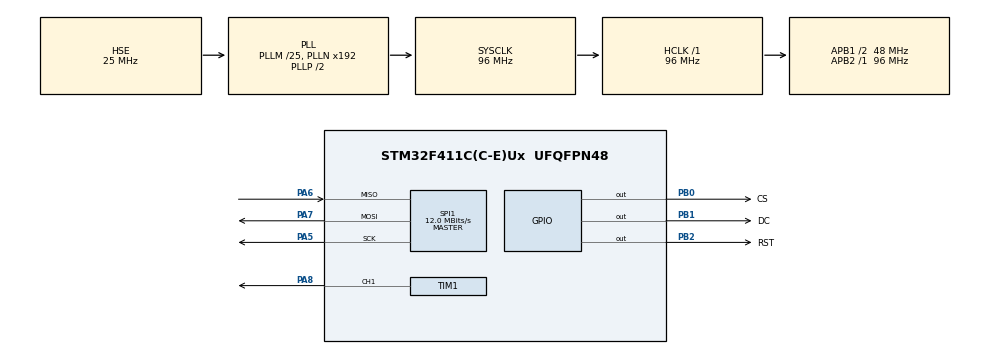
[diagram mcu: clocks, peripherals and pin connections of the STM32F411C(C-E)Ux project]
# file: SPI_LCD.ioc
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Mcu.Family=STM32F4
Mcu.Name=STM32F411C(C-E)Ux
Mcu.Package=UFQFPN48
NVIC.PriorityGroup=NVIC_PRIORITYGROUP_4
PA5.Mode=Full_Duplex_Master
PA5.Signal=SPI1_SCK
PA6.Mode=Full_Duplex_Master
PA6.Signal=SPI1_MISO
PA7.Mode=Full_Duplex_Master
PA7.Signal=SPI1_MOSI
PA8.Signal=S_TIM1_CH1
PB0.GPIO_Label=CS
PB0.PinState=GPIO_PIN_SET
PB0.Signal=GPIO_Output
PB1.GPIO_Label=DC
PB1.PinState=GPIO_PIN_SET
PB1.Signal=GPIO_Output
PB2.GPIO_Label=RST
PB2.PinState=GPIO_PIN_SET
PB2.Signal=GPIO_Output
PC14-OSC32_IN.Mode=LSE-External-Oscillator
PC14-OSC32_IN.Signal=RCC_OSC32_IN
PC15-OSC32_OUT.Mode=LSE-External-Oscillator
PC15-OSC32_OUT.Signal=RCC_OSC32_OUT
PH0\ -\ OSC_IN.Mode=HSE-External-Oscillator
PH0\ -\ OSC_IN.Signal=RCC_OSC_IN
PH1\ -\ OSC_OUT.Mode=HSE-External-Oscillator
PH1\ -\ OSC_OUT.Signal=RCC_OSC_OUT
ProjectManager.HeapSize=0x200
ProjectManager.StackSize=0x400
ProjectManager.TargetToolchain=Makefile
RCC.48MHZClocksFreq_Value=48000000
RCC.AHBFreq_Value=96000000
RCC.APB1CLKDivider=RCC_HCLK_DIV2
RCC.APB1Freq_Value=48000000
RCC.APB1TimFreq_Value=96000000
RCC.APB2Freq_Value=96000000
RCC.APB2TimFreq_Value=96000000
RCC.CortexFreq_Value=96000000
RCC.HCLKFreq_Value=96000000
RCC.HSE_VALUE=25000000
RCC.HSI_VALUE=16000000
RCC.PLLM=25
RCC.PLLSourceVirtual=RCC_PLLSOURCE_HSE
RCC.SYSCLKFreq_VALUE=96000000
RCC.SYSCLKSource=RCC_SYSCLKSOURCE_PLLCLK
RCC.VCOOutputFreq_Value=192000000
SH.S_TIM1_CH1.0=TIM1_CH1,PWM Generation1 CH1
SPI1.BaudRatePrescaler=SPI_BAUDRATEPRESCALER_8
SPI1.CalculateBaudRate=12.0 MBits/s
SPI1.Direction=SPI_DIRECTION_2LINES
SPI1.Mode=SPI_MODE_MASTER
SPI1.VirtualType=VM_MASTER
TIM1.AutoReloadPreload=TIM_AUTORELOAD_PRELOAD_ENABLE
TIM1.Channel-PWM\ Generation1\ CH1=TIM_CHANNEL_1
TIM1.Period=1000-1
board=custom

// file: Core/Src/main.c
/* USER CODE BEGIN Header */
/**
  ******************************************************************************
  * @file           : main.c
  * @brief          : Main program body
  ******************************************************************************
  * @attention
  *
  * Copyright (c) 2025 STMicroelectronics.
  * All rights reserved.
  *
  * This software is licensed under terms that can be found in the LICENSE file
  * in the root directory of this software component.
  * If no LICENSE file comes with this software, it is provided AS-IS.
  *
  ******************************************************************************
  */
/* USER CODE END Header */
#include "main.h"

/* USER CODE BEGIN Includes */
#include "lcd.h"

/* USER CODE END Includes */

SPI_HandleTypeDef hspi1;

TIM_HandleTypeDef htim1;

void SystemClock_Config(void);
static void MX_GPIO_Init(void);
static void MX_SPI1_Init(void);
static void MX_TIM1_Init(void);

int main(void)
{

  /* MCU Configuration--------------------------------------------------------*/

  /* Reset of all peripherals, Initializes the Flash interface and the Systick. */
  HAL_Init();

  /* Configure the system clock */
  SystemClock_Config();

  /* Initialize all configured peripherals */
  MX_GPIO_Init();
  MX_SPI1_Init();
  MX_TIM1_Init();
  /* USER CODE BEGIN 2 */

  LCD_1in28_test();

  /* USER CODE END 2 */

  /* Infinite loop */
  while (1)
  {

  }
}

void SystemClock_Config(void)
{
  RCC_OscInitTypeDef RCC_OscInitStruct = {0};
  RCC_ClkInitTypeDef RCC_ClkInitStruct = {0};

  /** Configure the main internal regulator output voltage
  */
  __HAL_RCC_PWR_CLK_ENABLE();
  __HAL_PWR_VOLTAGESCALING_CONFIG(PWR_REGULATOR_VOLTAGE_SCALE1);

  /** Initializes the RCC Oscillators according to the specified parameters
  * in the RCC_OscInitTypeDef structure.
  */
  RCC_OscInitStruct.OscillatorType = RCC_OSCILLATORTYPE_HSE;
  RCC_OscInitStruct.HSEState = RCC_HSE_ON;
  RCC_OscInitStruct.PLL.PLLState = RCC_PLL_ON;
  RCC_OscInitStruct.PLL.PLLSource = RCC_PLLSOURCE_HSE;
  RCC_OscInitStruct.PLL.PLLM = 25;
  RCC_OscInitStruct.PLL.PLLN = 192;
  RCC_OscInitStruct.PLL.PLLP = RCC_PLLP_DIV2;
  RCC_OscInitStruct.PLL.PLLQ = 4;
  if (HAL_RCC_OscConfig(&RCC_OscInitStruct) != HAL_OK)
  {
    Error_Handler();
  }

  /** Initializes the CPU, AHB and APB buses clocks
  */
  RCC_ClkInitStruct.ClockType = RCC_CLOCKTYPE_HCLK|RCC_CLOCKTYPE_SYSCLK
                              |RCC_CLOCKTYPE_PCLK1|RCC_CLOCKTYPE_PCLK2;
  RCC_ClkInitStruct.SYSCLKSource = RCC_SYSCLKSOURCE_PLLCLK;
  RCC_ClkInitStruct.AHBCLKDivider = RCC_SYSCLK_DIV1;
  RCC_ClkInitStruct.APB1CLKDivider = RCC_HCLK_DIV2;
  RCC_ClkInitStruct.APB2CLKDivider = RCC_HCLK_DIV1;

  if (HAL_RCC_ClockConfig(&RCC_ClkInitStruct, FLASH_LATENCY_3) != HAL_OK)
  {
    Error_Handler();
  }
}

static void MX_SPI1_Init(void)
{

  /* SPI1 parameter configuration*/
  hspi1.Instance = SPI1;
  hspi1.Init.Mode = SPI_MODE_MASTER;
  hspi1.Init.Direction = SPI_DIRECTION_2LINES;
  hspi1.Init.DataSize = SPI_DATASIZE_8BIT;
  hspi1.Init.CLKPolarity = SPI_POLARITY_LOW;
  hspi1.Init.CLKPhase = SPI_PHASE_1EDGE;
  hspi1.Init.NSS = SPI_NSS_SOFT;
  hspi1.Init.BaudRatePrescaler = SPI_BAUDRATEPRESCALER_8;
  hspi1.Init.FirstBit = SPI_FIRSTBIT_MSB;
  hspi1.Init.TIMode = SPI_TIMODE_DISABLE;
  hspi1.Init.CRCCalculation = SPI_CRCCALCULATION_DISABLE;
  hspi1.Init.CRCPolynomial = 10;
  if (HAL_SPI_Init(&hspi1) != HAL_OK)
  {
    Error_Handler();
  }

}

static void MX_TIM1_Init(void)
{

  TIM_MasterConfigTypeDef sMasterConfig = {0};
  TIM_OC_InitTypeDef sConfigOC = {0};
  TIM_BreakDeadTimeConfigTypeDef sBreakDeadTimeConfig = {0};

  htim1.Instance = TIM1;
  htim1.Init.Prescaler = 0;
  htim1.Init.CounterMode = TIM_COUNTERMODE_UP;
  htim1.Init.Period = 1000-1;
  htim1.Init.ClockDivision = TIM_CLOCKDIVISION_DIV1;
  htim1.Init.RepetitionCounter = 0;
  htim1.Init.AutoReloadPreload = TIM_AUTORELOAD_PRELOAD_ENABLE;
  if (HAL_TIM_PWM_Init(&htim1) != HAL_OK)
  {
    Error_Handler();
  }
  sMasterConfig.MasterOutputTrigger = TIM_TRGO_RESET;
  sMasterConfig.MasterSlaveMode = TIM_MASTERSLAVEMODE_DISABLE;
  if (HAL_TIMEx_MasterConfigSynchronization(&htim1, &sMasterConfig) != HAL_OK)
  {
    Error_Handler();
  }
  sConfigOC.OCMode = TIM_OCMODE_PWM1;
  sConfigOC.Pulse = 0;
  sConfigOC.OCPolarity = TIM_OCPOLARITY_HIGH;
  sConfigOC.OCNPolarity = TIM_OCNPOLARITY_HIGH;
  sConfigOC.OCFastMode = TIM_OCFAST_DISABLE;
  sConfigOC.OCIdleState = TIM_OCIDLESTATE_RESET;
  sConfigOC.OCNIdleState = TIM_OCNIDLESTATE_RESET;
  if (HAL_TIM_PWM_ConfigChannel(&htim1, &sConfigOC, TIM_CHANNEL_1) != HAL_OK)
  {
    Error_Handler();
  }
  sBreakDeadTimeConfig.OffStateRunMode = TIM_OSSR_DISABLE;
  sBreakDeadTimeConfig.OffStateIDLEMode = TIM_OSSI_DISABLE;
  sBreakDeadTimeConfig.LockLevel = TIM_LOCKLEVEL_OFF;
  sBreakDeadTimeConfig.DeadTime = 0;
  sBreakDeadTimeConfig.BreakState = TIM_BREAK_DISABLE;
  sBreakDeadTimeConfig.BreakPolarity = TIM_BREAKPOLARITY_HIGH;
  sBreakDeadTimeConfig.AutomaticOutput = TIM_AUTOMATICOUTPUT_DISABLE;
  if (HAL_TIMEx_ConfigBreakDeadTime(&htim1, &sBreakDeadTimeConfig) != HAL_OK)
  {
    Error_Handler();
  }
  HAL_TIM_MspPostInit(&htim1);

}

static void MX_GPIO_Init(void)
{
  GPIO_InitTypeDef GPIO_InitStruct = {0};

  /* GPIO Ports Clock Enable */
  __HAL_RCC_GPIOC_CLK_ENABLE();
  __HAL_RCC_GPIOH_CLK_ENABLE();
  __HAL_RCC_GPIOA_CLK_ENABLE();
  __HAL_RCC_GPIOB_CLK_ENABLE();

  /*Configure GPIO pin Output Level */
  HAL_GPIO_WritePin(GPIOB, CS_Pin|DC_Pin|RST_Pin, GPIO_PIN_SET);

  /*Configure GPIO pins : CS_Pin DC_Pin RST_Pin */
  GPIO_InitStruct.Pin = CS_Pin|DC_Pin|RST_Pin;
  GPIO_InitStruct.Mode = GPIO_MODE_OUTPUT_PP;
  GPIO_InitStruct.Pull = GPIO_NOPULL;
  GPIO_InitStruct.Speed = GPIO_SPEED_FREQ_LOW;
  HAL_GPIO_Init(GPIOB, &GPIO_InitStruct);

}

void Error_Handler(void)
{
  __disable_irq();
  while (1)
  {
  }
}
